# dwt register map
Vendor: Texas Instruments
Peripheral module from a debugger description file (folder MSP432).
Registers are 32-bit, read-write, no defined reset value unless marked. A register's access mark holds for its fields unless they carry their own. Offsets are as the file gives them; lines under a group give offsets from that group; [hi:lo] are bit positions; {n}, {i} and the like mark numbered series; 'fields as' and 'values as' point back to an identical list; <NAME> marks a mode.

## DWT
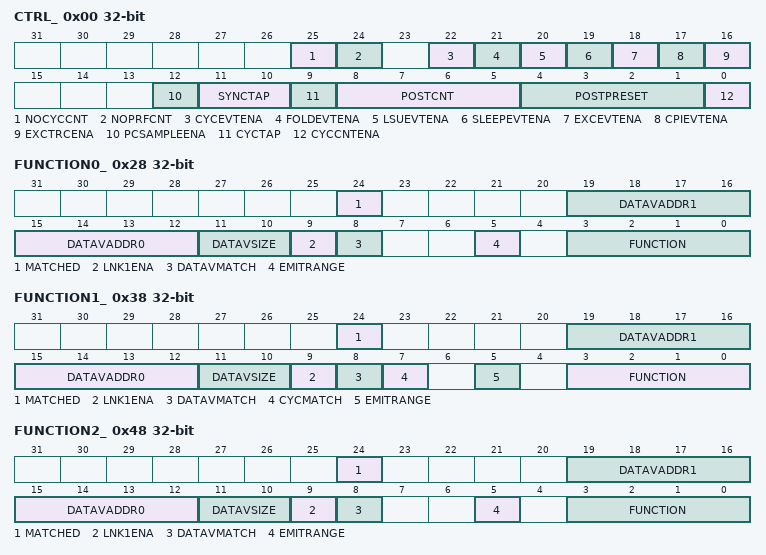
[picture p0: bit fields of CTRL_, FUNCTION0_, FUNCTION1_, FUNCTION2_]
0x00 CTRL_ — DWT Control Register
  [25] NOCYCCNT — When set, DWT_CYCCNT is not supported.
  [24] NOPRFCNT — When set, DWT_FOLDCNT, DWT_LSUCNT, DWT_SLEEPCNT, DWT_EXCCNT, an
  [22] CYCEVTENA — Enables Cycle count event
    0=CYCEVTENA__0 (Cycle count events disabled.); 1=CYCEVTENA__1 (Cycle count events enabled.)
  [21] FOLDEVTENA — Enables Folded instruction count event
    0=FOLDEVTENA__0 (Folded instruction count events disabled.); 1=FOLDEVTENA__1 (Folded instruction count events enabled.)
  [20] LSUEVTENA — Enables LSU count event
    0=LSUEVTENA__0 (LSU count events disabled.); 1=LSUEVTENA__1 (LSU count events enabled.)
  [19] SLEEPEVTENA — Enables Sleep count event
    0=SLEEPEVTENA__0 (Sleep count events disabled.); 1=SLEEPEVTENA__1 (Sleep count events enabled.)
  [18] EXCEVTENA — Enables Interrupt overhead event
    0=EXCEVTENA__0 (Interrupt overhead event disabled.); 1=EXCEVTENA__1 (Interrupt overhead event enabled.)
  [17] CPIEVTENA — Enables CPI count event
    0=CPIEVTENA__0 (CPI counter events disabled.); 1=CPIEVTENA__1 (CPI counter events enabled.)
  [16] EXCTRCENA — Enables Interrupt event tracing. Reset clears the EXCEVTENA bit.
    0=EXCTRCENA__0 (interrupt event trace disabled.); 1=EXCTRCENA__1 (interrupt event trace enabled.)
  [12] PCSAMPLEENA — Enables PC Sampling event
    0=PCSAMPLEENA__0 (PC Sampling event disabled.); 1=PCSAMPLEENA__1 (Sampling event enabled.)
  [11:10] SYNCTAP — Feeds a synchronization pulse to the ITM SYNCENA control
    0=SYNCTAP__0 (Disabled. No synch counting.); 1=SYNCTAP__1 (Tap at CYCCNT bit 24.); 2=SYNCTAP__2 (Tap at CYCCNT bit 26.); 3=SYNCTAP__3 (Tap at CYCCNT bit 28.)
  [9] CYCTAP — Selects a tap on the DWT_CYCCNT register
    0=CYCTAP__0 (selects bit [6] to tap); 1=CYCTAP__1 (selects bit [10] to tap.)
  [8:5] POSTCNT — Post-scalar counter for CYCTAP
  [4:1] POSTPRESET — Reload value for POSTCNT, bits [8:5], post-scalar counter
  [0] CYCCNTENA — Enable the CYCCNT counter
0x04 CYCCNT_ — DWT Current PC Sampler Cycle Count Register
  [31:0] CYCCNT — Current PC Sampler Cycle Counter count value
0x08 CPICNT_ — DWT CPI Count Register
  [7:0] CPICNT — Current CPI counter value
0x0C EXCCNT_ — DWT Exception Overhead Count Register
  [7:0] EXCCNT — Current interrupt overhead counter value
0x10 SLEEPCNT_ — DWT Sleep Count Register
  [7:0] SLEEPCNT — Sleep counter
0x14 LSUCNT_ — DWT LSU Count Register
  [7:0] LSUCNT — LSU counter
0x18 FOLDCNT_ — DWT Fold Count Register
  [7:0] FOLDCNT — This counts the total number folded instructions
0x1C PCSR_ — DWT Program Counter Sample Register
  [31:0] EIASAMPLE — Execution instruction address sample, or 0xFFFFFFFF if the core
{0x20+0x10*i} COMP{i}_ (i=0..3) — DWT Comparator Register {i}
  [31:0] COMP — Data value to compare against PC and the data address as given
{0x24+0x10*i} MASK{i}_ (i=0..3) — DWT Mask Register {i}
  [3:0] MASK — Mask on data address when matching against COMP
0x28 FUNCTION0_ — DWT Function Register 0
  [24] MATCHED — This bit is set when the comparator matches, and indicates that
  [19:16] DATAVADDR1 — Identity of a second linked address comparator for data value m
  [15:12] DATAVADDR0 — Identity of a linked address comparator for data value matching
  [11:10] DATAVSIZE — Defines the size of the data in the COMP register that is to be
    0=DATAVSIZE__0 (byte); 1=DATAVSIZE__1 (halfword); 2=DATAVSIZE__2 (word); 3=DATAVSIZE__3 (Unpredictable.)
  [9] LNK1ENA
    0=LNK1ENA__0 (DATAVADDR1 not supported); 1=LNK1ENA__1 (DATAVADDR1 supported (enabled).)
  [8] DATAVMATCH — This bit is only available in comparator 1
  [5] EMITRANGE
  [3:0] FUNCTION — Function settings
    0=FUNCTION__0 (Disabled); 1=FUNCTION__1 (EMITRANGE = 0, sample and emit PC through ITM); 2=FUNCTION__2 (EMITRANGE = 0, emit data through ITM on read and write); 3=FUNCTION__3 (EMITRANGE = 0, sample PC and data value through ITM on read or); 4=FUNCTION__4 (Watchpoint on PC match.); 5=FUNCTION__5 (Watchpoint on read.); 6=FUNCTION__6 (Watchpoint on write.); 7=FUNCTION__7 (Watchpoint on read or write.); 8=FUNCTION__8 (ETM trigger on PC match); 9=FUNCTION__9 (ETM trigger on read); 10=FUNCTION__10 (ETM trigger on write); 11=FUNCTION__11 (ETM trigger on read or write); 12=FUNCTION__12 (EMITRANGE = 0, sample data for read transfers); 13=FUNCTION__13 (EMITRANGE = 0, sample data for write transfers); 14=FUNCTION__14 (EMITRANGE = 0, sample PC + data for read transfers); 15=FUNCTION__15 (EMITRANGE = 0, sample PC + data for write transfers)
0x38 FUNCTION1_ — DWT Function Register 1
  [24] MATCHED — This bit is set when the comparator matches, and indicates that
  [19:16] DATAVADDR1 — Identity of a second linked address comparator for data value m
  [15:12] DATAVADDR0 — Identity of a linked address comparator for data value matching
  [11:10] DATAVSIZE — Defines the size of the data in the COMP register that is to be
    values as FUNCTION0_.DATAVSIZE
  [9] LNK1ENA
    values as FUNCTION0_.LNK1ENA
  [8] DATAVMATCH — This bit is only available in comparator 1
  [7] CYCMATCH — Only available in comparator 0
  [5] EMITRANGE
  [3:0] FUNCTION — Function settings
    values as FUNCTION0_.FUNCTION
0x48 FUNCTION2_ — DWT Function Register 2
  fields as FUNCTION0_
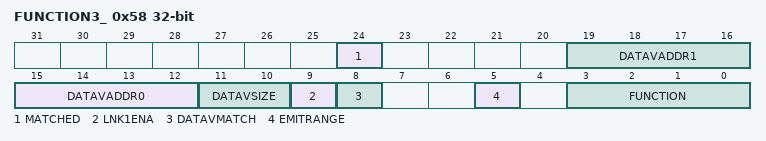
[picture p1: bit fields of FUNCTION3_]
0x58 FUNCTION3_ — DWT Function Register 3
  fields as FUNCTION0_
